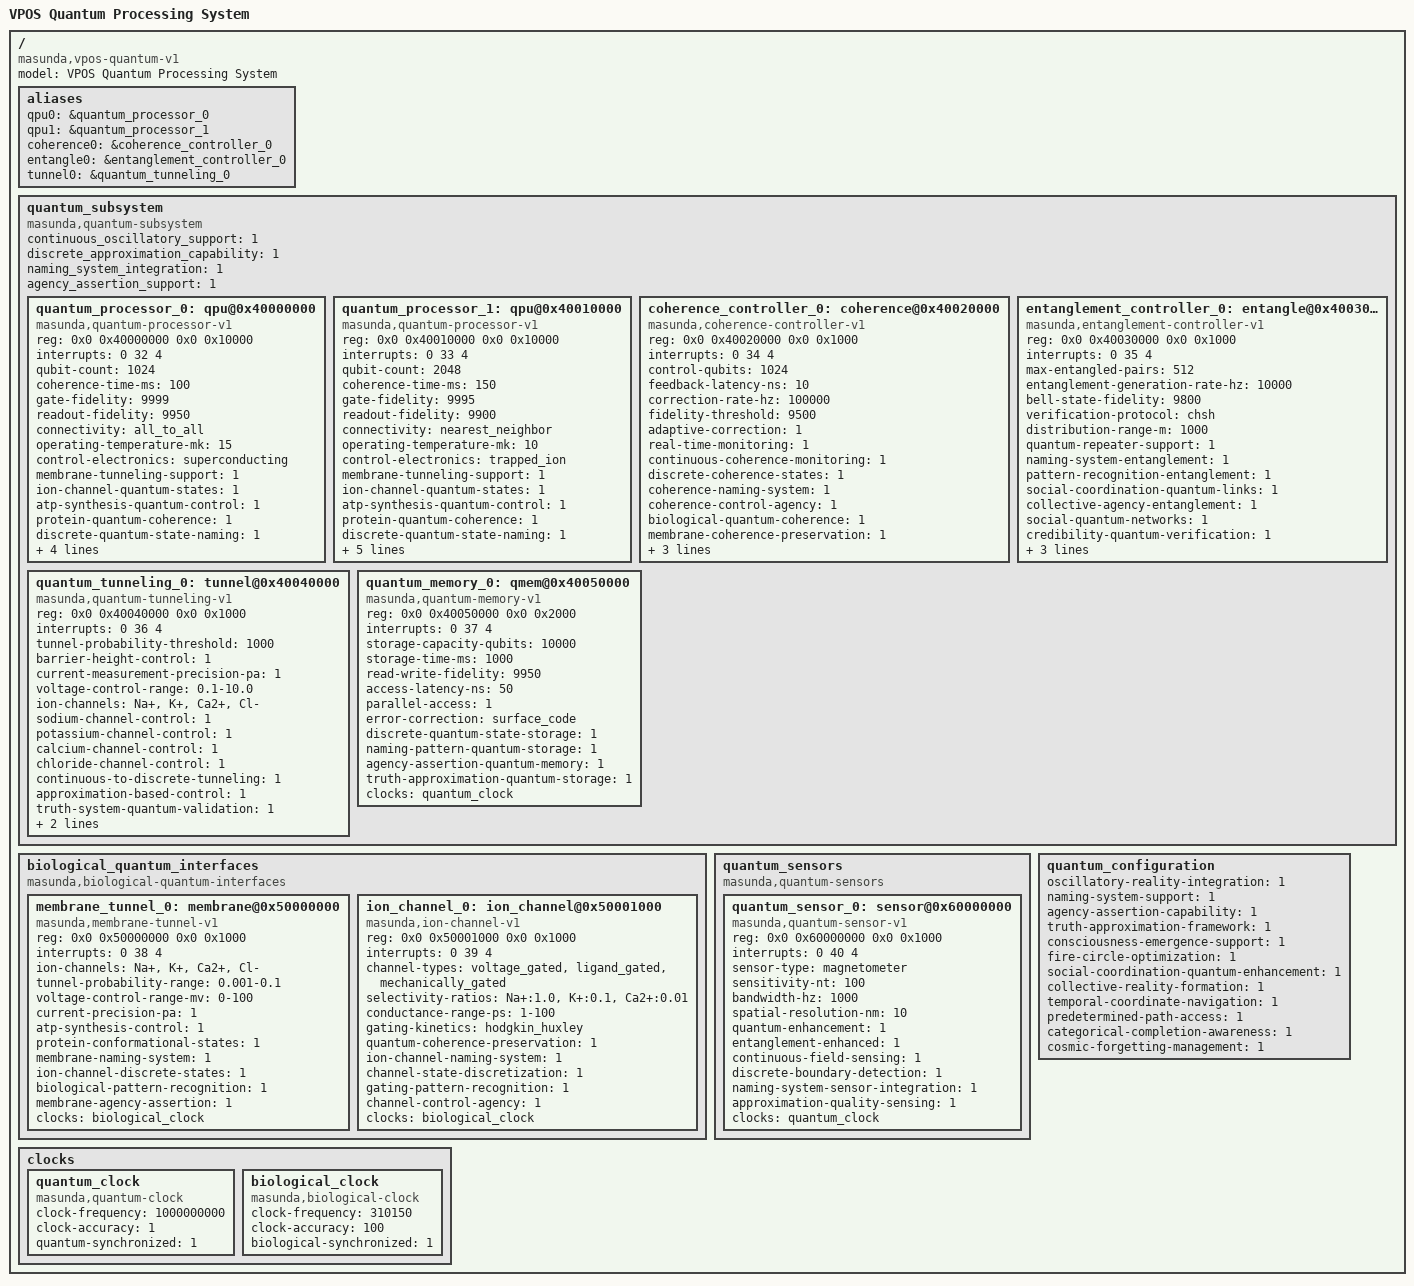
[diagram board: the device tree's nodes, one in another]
/*
 * VPOS Quantum Devices Device Tree Source
 * Masunda Temporal Coordinate Navigator - Quantum Hardware Definition
 * 
 * This device tree defines quantum processing units, coherence controllers,
 * entanglement managers, and biological quantum interfaces
 */

/dts-v1/;

/ {
    model = "VPOS Quantum Processing System";
    compatible = "masunda,vpos-quantum-v1";
    
    #address-cells = <2>;
    #size-cells = <2>;

    aliases {
        qpu0 = &quantum_processor_0;
        qpu1 = &quantum_processor_1;
        coherence0 = &coherence_controller_0;
        entangle0 = &entanglement_controller_0;
        tunnel0 = &quantum_tunneling_0;
    };

    quantum_subsystem {
        compatible = "masunda,quantum-subsystem";
        status = "okay";
        
        /* Oscillatory reality integration */
        continuous_oscillatory_support = <1>;
        discrete_approximation_capability = <1>;
        naming_system_integration = <1>;
        agency_assertion_support = <1>;
        
        quantum_processor_0: qpu@0x40000000 {
            compatible = "masunda,quantum-processor-v1";
            reg = <0x0 0x40000000 0x0 0x10000>;
            interrupts = <0 32 4>;
            status = "okay";
            
            /* QPU properties */
            qubit-count = <1024>;
            coherence-time-ms = <100>;
            gate-fidelity = <9999>; /* 0.9999 * 10000 */
            readout-fidelity = <9950>; /* 0.995 * 10000 */
            connectivity = "all_to_all";
            operating-temperature-mk = <15>;
            control-electronics = "superconducting";
            
            /* Biological quantum integration */
            membrane-tunneling-support = <1>;
            ion-channel-quantum-states = <1>;
            atp-synthesis-quantum-control = <1>;
            protein-quantum-coherence = <1>;
            
            /* Naming system quantum properties */
            discrete-quantum-state-naming = <1>;
            quantum-pattern-recognition = <1>;
            oscillatory-approximation-capability = <1>;
            quantum-agency-assertion = <1>;
            
            clocks = <&quantum_clock>;
            clock-names = "quantum_ref";
        };
        
        quantum_processor_1: qpu@0x40010000 {
            compatible = "masunda,quantum-processor-v1";
            reg = <0x0 0x40010000 0x0 0x10000>;
            interrupts = <0 33 4>;
            status = "okay";
            
            /* QPU properties */
            qubit-count = <2048>;
            coherence-time-ms = <150>;
            gate-fidelity = <9995>; /* 0.9995 * 10000 */
            readout-fidelity = <9900>; /* 0.99 * 10000 */
            connectivity = "nearest_neighbor";
            operating-temperature-mk = <10>;
            control-electronics = "trapped_ion";
            
            /* Enhanced biological integration */
            membrane-tunneling-support = <1>;
            ion-channel-quantum-states = <1>;
            atp-synthesis-quantum-control = <1>;
            protein-quantum-coherence = <1>;
            
            /* Advanced naming system properties */
            discrete-quantum-state-naming = <1>;
            quantum-pattern-recognition = <1>;
            oscillatory-approximation-capability = <1>;
            quantum-agency-assertion = <1>;
            truth-approximation-quantum-support = <1>;
            
            clocks = <&quantum_clock>;
            clock-names = "quantum_ref";
        };
        
        coherence_controller_0: coherence@0x40020000 {
            compatible = "masunda,coherence-controller-v1";
            reg = <0x0 0x40020000 0x0 0x1000>;
            interrupts = <0 34 4>;
            status = "okay";
            
            /* Coherence properties */
            control-qubits = <1024>;
            feedback-latency-ns = <10>;
            correction-rate-hz = <100000>;
            fidelity-threshold = <9500>; /* 0.95 * 10000 */
            adaptive-correction = <1>;
            real-time-monitoring = <1>;
            
            /* Oscillatory coherence properties */
            continuous-coherence-monitoring = <1>;
            discrete-coherence-states = <1>;
            coherence-naming-system = <1>;
            coherence-control-agency = <1>;
            
            /* Biological coherence support */
            biological-quantum-coherence = <1>;
            membrane-coherence-preservation = <1>;
            protein-conformational-coherence = <1>;
            atp-coherence-coupling = <1>;
            
            clocks = <&quantum_clock>;
            clock-names = "coherence_ref";
        };
        
        entanglement_controller_0: entangle@0x40030000 {
            compatible = "masunda,entanglement-controller-v1";
            reg = <0x0 0x40030000 0x0 0x1000>;
            interrupts = <0 35 4>;
            status = "okay";
            
            /* Entanglement properties */
            max-entangled-pairs = <512>;
            entanglement-generation-rate-hz = <10000>;
            bell-state-fidelity = <9800>; /* 0.98 * 10000 */
            verification-protocol = "chsh";
            distribution-range-m = <1000>;
            quantum-repeater-support = <1>;
            
            /* Social coordination entanglement */
            naming-system-entanglement = <1>;
            pattern-recognition-entanglement = <1>;
            social-coordination-quantum-links = <1>;
            collective-agency-entanglement = <1>;
            
            /* Fire circle quantum networking */
            social-quantum-networks = <1>;
            credibility-quantum-verification = <1>;
            truth-assessment-quantum-enhancement = <1>;
            collective-decision-quantum-support = <1>;
            
            clocks = <&quantum_clock>;
            clock-names = "entangle_ref";
        };
        
        quantum_tunneling_0: tunnel@0x40040000 {
            compatible = "masunda,quantum-tunneling-v1";
            reg = <0x0 0x40040000 0x0 0x1000>;
            interrupts = <0 36 4>;
            status = "okay";
            
            /* Tunneling properties */
            tunnel-probability-threshold = <1000>; /* 0.001 * 1000000 */
            barrier-height-control = <1>;
            current-measurement-precision-pa = <1>;
            voltage-control-range = "0.1-10.0";
            
            /* Ion channel support */
            ion-channels = "Na+", "K+", "Ca2+", "Cl-";
            sodium-channel-control = <1>;
            potassium-channel-control = <1>;
            calcium-channel-control = <1>;
            chloride-channel-control = <1>;
            
            /* Reality formation tunneling */
            continuous-to-discrete-tunneling = <1>;
            approximation-based-control = <1>;
            truth-system-quantum-validation = <1>;
            agency-assertion-quantum-support = <1>;
            
            clocks = <&quantum_clock>;
            clock-names = "tunnel_ref";
        };
        
        quantum_memory_0: qmem@0x40050000 {
            compatible = "masunda,quantum-memory-v1";
            reg = <0x0 0x40050000 0x0 0x2000>;
            interrupts = <0 37 4>;
            status = "okay";
            
            /* Memory properties */
            storage-capacity-qubits = <10000>;
            storage-time-ms = <1000>;
            read-write-fidelity = <9950>; /* 0.995 * 10000 */
            access-latency-ns = <50>;
            parallel-access = <1>;
            error-correction = "surface_code";
            
            /* Naming system memory */
            discrete-quantum-state-storage = <1>;
            naming-pattern-quantum-storage = <1>;
            agency-assertion-quantum-memory = <1>;
            truth-approximation-quantum-storage = <1>;
            
            clocks = <&quantum_clock>;
            clock-names = "qmem_ref";
        };
    };
    
    biological_quantum_interfaces {
        compatible = "masunda,biological-quantum-interfaces";
        status = "okay";
        
        membrane_tunnel_0: membrane@0x50000000 {
            compatible = "masunda,membrane-tunnel-v1";
            reg = <0x0 0x50000000 0x0 0x1000>;
            interrupts = <0 38 4>;
            status = "okay";
            
            /* Membrane properties */
            ion-channels = "Na+", "K+", "Ca2+", "Cl-";
            tunnel-probability-range = "0.001-0.1";
            voltage-control-range-mv = "0-100";
            current-precision-pa = <1>;
            atp-synthesis-control = <1>;
            protein-conformational-states = <1>;
            
            /* Biological naming system integration */
            membrane-naming-system = <1>;
            ion-channel-discrete-states = <1>;
            biological-pattern-recognition = <1>;
            membrane-agency-assertion = <1>;
            
            clocks = <&biological_clock>;
            clock-names = "membrane_ref";
        };
        
        ion_channel_0: ion_channel@0x50001000 {
            compatible = "masunda,ion-channel-v1";
            reg = <0x0 0x50001000 0x0 0x1000>;
            interrupts = <0 39 4>;
            status = "okay";
            
            /* Ion channel properties */
            channel-types = "voltage_gated", "ligand_gated", "mechanically_gated";
            selectivity-ratios = "Na+:1.0", "K+:0.1", "Ca2+:0.01";
            conductance-range-ps = "1-100";
            gating-kinetics = "hodgkin_huxley";
            quantum-coherence-preservation = <1>;
            
            /* Biological quantum naming */
            ion-channel-naming-system = <1>;
            channel-state-discretization = <1>;
            gating-pattern-recognition = <1>;
            channel-control-agency = <1>;
            
            clocks = <&biological_clock>;
            clock-names = "ion_channel_ref";
        };
    };
    
    quantum_sensors {
        compatible = "masunda,quantum-sensors";
        status = "okay";
        
        quantum_sensor_0: sensor@0x60000000 {
            compatible = "masunda,quantum-sensor-v1";
            reg = <0x0 0x60000000 0x0 0x1000>;
            interrupts = <0 40 4>;
            status = "okay";
            
            /* Sensor properties */
            sensor-type = "magnetometer";
            sensitivity-nt = <100>; /* 0.1 * 1000 */
            bandwidth-hz = <1000>;
            spatial-resolution-nm = <10>;
            quantum-enhancement = <1>;
            entanglement-enhanced = <1>;
            
            /* Reality sensing properties */
            continuous-field-sensing = <1>;
            discrete-boundary-detection = <1>;
            naming-system-sensor-integration = <1>;
            approximation-quality-sensing = <1>;
            
            clocks = <&quantum_clock>;
            clock-names = "sensor_ref";
        };
    };
    
    clocks {
        quantum_clock: quantum_clock {
            compatible = "masunda,quantum-clock";
            #clock-cells = <0>;
            clock-frequency = <1000000000>; /* 1 GHz */
            clock-accuracy = <1>; /* 1 ppm */
            quantum-synchronized = <1>;
        };
        
        biological_clock: biological_clock {
            compatible = "masunda,biological-clock";
            #clock-cells = <0>;
            clock-frequency = <310150>; /* Body temperature in mK * 1000 */
            clock-accuracy = <100>; /* 100 ppm */
            biological-synchronized = <1>;
        };
    };
    
    quantum_configuration {
        /* Global quantum system configuration */
        oscillatory-reality-integration = <1>;
        naming-system-support = <1>;
        agency-assertion-capability = <1>;
        truth-approximation-framework = <1>;
        consciousness-emergence-support = <1>;
        fire-circle-optimization = <1>;
        social-coordination-quantum-enhancement = <1>;
        collective-reality-formation = <1>;
        
        /* Masunda temporal coordinate navigator */
        temporal-coordinate-navigation = <1>;
        predetermined-path-access = <1>;
        categorical-completion-awareness = <1>;
        cosmic-forgetting-management = <1>;
    };
}; 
